# GD32E511_512 register map
File version: 1.0
CPU: CM33 r0p4, little endian, MPU, FPU, 4 interrupt priority bits
Registers are 32-bit, read-write, reset 0x0 unless marked. A register's access mark holds for its fields unless they carry their own. Offsets are from the block's base; [hi:lo] are bit positions; {n}, {i} and the like mark numbered series.

## I3C — Improved inter-integrated circuit interface
Base 0x40015C00
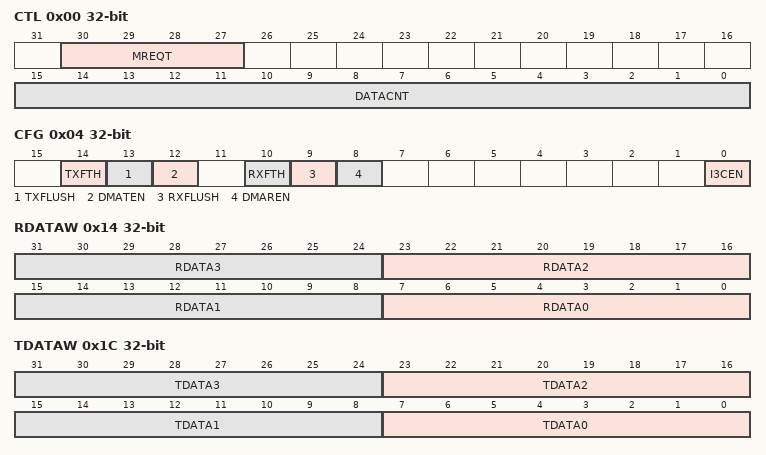
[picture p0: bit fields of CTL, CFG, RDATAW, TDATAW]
0x00 CTL wo — Control register
  [30:27] MREQT — Target message request type
  [15:0] DATACNT — The number of data bytes transmitted
0x04 CFG — Configuration register
  [14] TXFTH — TX-FIFO threshold
  [13] TXFLUSH — TX-FIFO flush
  [12] DMATEN — TX-FIFO DMA request enable
  [10] RXFTH — RX-FIFO threshold
  [9] RXFLUSH — RX-FIFO flush.
  [8] DMAREN — RX-FIFO DMA request enable
  [0] I3CEN — I3C enable
0x10 RDATAB ro — Receive data byte register
  [7:0] RDATA0 — 8-bit received data
0x14 RDATAW ro — Receive data word register
  [8n+7:8n] RDATA{n} (n=0..3) — 8-bit received data
0x18 TDATAB wo — Transmit data byte register
  [7:0] TDATA0 — 8-bit data to transmit
0x1C TDATAW wo — Transmit data word register
  [8n+7:8n] TDATA{n} (n=0..3) — 8-bit transmit data
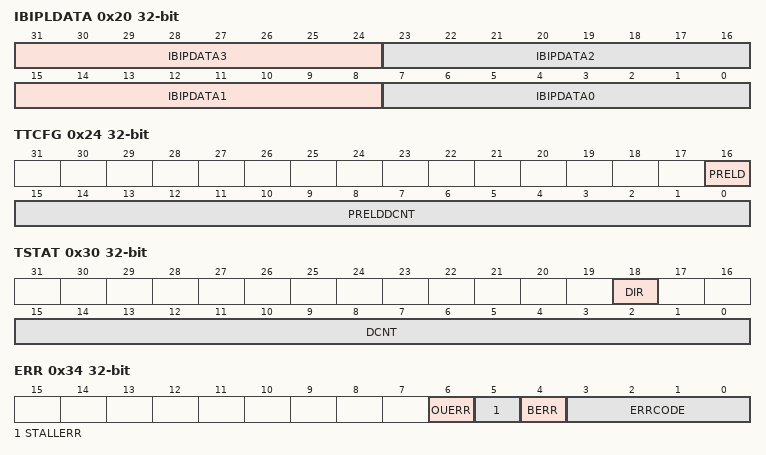
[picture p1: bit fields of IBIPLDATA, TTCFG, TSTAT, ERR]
0x20 IBIPLDATA — IBI Payload data register
  [31:24] IBIPDATA3 — 8-bit IBI payload data
  [23:16] IBIPDATA2 — 8-bit IBI payload data
  [15:8] IBIPDATA1 — 8-bit IBI payload data
  [7:0] IBIPDATA0 — 8-bit IBI payload data (earliest byte on I3C bus, MDB[7:0] mandatory data byte). Data byte to go with an IBI, if enabled for it. If enabled (BCR2 bit is set), then it is required.
0x24 TTCFG — Target transmit configuration registe
  [16] PRELD — Preload of the TX-FIFO
  [15:0] PRELDDCNT — The number of bytes preloaded into the TXFIFO, used in conjunction with the PRELD bit.
0x30 TSTAT ro — Transmit status register
  [18] DIR — I3C bus message transmit direction
  [15:0] DCNT — During the dynamic address assignment process (ENTDAA CCC), this bit field indicates the number of transmitted bytes
0x34 ERR ro — Error status register
  [6] OUERR — RXFIFO overrun or TXFIFO underrun
  [5] STALLERR — SCL stall error
  [4] BERR — Bus protocol error
  [3:0] ERRCODE — Protocol error code/type
0x40 RMES ro — Received message register
  [15:8] RCODE — Received CCC code
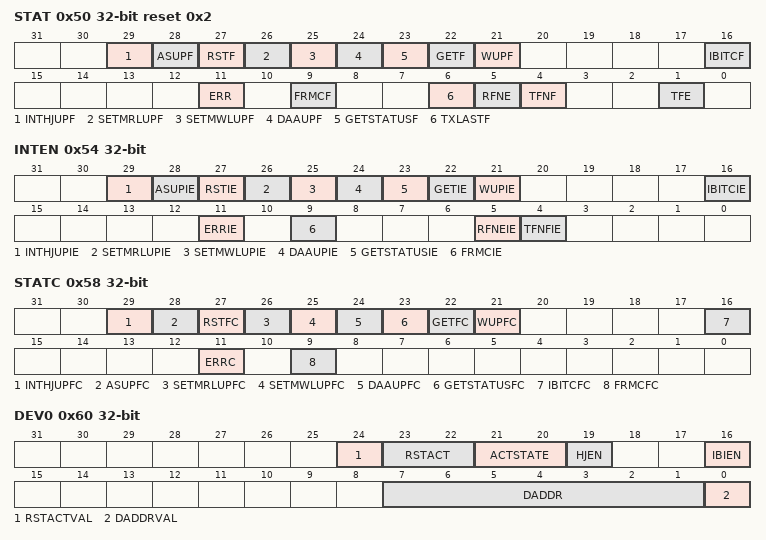
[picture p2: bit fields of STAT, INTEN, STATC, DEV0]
0x50 STAT ro reset 0x2 — Status register
  [29] INTHJUPF — Interrupt/hot-join update flag
  [28] ASUPF — Activity state update flag
  [27] RSTF — Reset pattern flag
  [26] SETMRLUPF — Maximum read length update flag
  [25] SETMWLUPF — Maximum write length update flag
  [24] DAAUPF — Dynamic address update flag
  [23] GETSTATUSF — Get status flag
  [22] GETF — Get flag
  [21] WUPF — Wake-up/missed start flag
  [16] IBITCF — IBI transmit completed flag
  [11] ERR — Error flag
  [9] FRMCF — Private read/write frame completed flag
  [6] TXLASTF — TXFIFO last data byte/word flag (data or word depending upon TXFTH in the I3C_CFG register)
  [5] RFNE — RX-FIFO not empty flag
  [4] TFNF — TX-FIFO not full flag
  [1] TFE — TX-FIFO empty flag
0x54 INTEN — Interrupt enable register
  [29] INTHJUPIE — ENEC/DISEC CCC interrupt enable
  [28] ASUPIE — ENTASx CCC interrupt enable
  [27] RSTIE — Reset pattern interrupt enable
  [26] SETMRLUPIE — SETMRL CCC interrupt enable
  [25] SETMWLUPIE — SETMWL CCC interrupt enable
  [24] DAAUPIE — ENTDAA/RSTDAA/SETNEWDA CCC interrupt enable
  [23] GETSTATUSIE — GETSTATUS CCC format 1 interrupt enable
  [22] GETIE — GETxxx CCC interrupt enable (except GETSTATUS of format 1)
  [21] WUPIE — Wake-up interrupt enable
  [16] IBITCIE — IBI completed interrupt enable
  [11] ERRIE — Error interrupt enable
  [9] FRMCIE — Frame completed interrupt enable
  [5] RFNEIE — RX-FIFO not empty interrupt enable
  [4] TFNFIE — TX-FIFO not full interrupt enable
0x58 STATC wo — Status clear register
  [29] INTHJUPFC — Set this bit to clear INTHJUPF flag in I3C_STAT register
  [28] ASUPFC — Set this bit to clear ASUPF flag in I3C_STAT register
  [27] RSTFC — Set this bit to clear RSTF flag in I3C_STAT register
  [26] SETMRLUPFC — Set this bit to clear SETMRLUPF flag in I3C_STAT register
  [25] SETMWLUPFC — Set this bit to clear SETMWLUPF flag in I3C_STAT register
  [24] DAAUPFC — Set this bit to clear DAAUPF flag in I3C_STAT register
  [23] GETSTATUSFC — Set this bit to clear GETSTATUSF flag in I3C_STAT register
  [22] GETFC — Set this bit to clear GETF flag in I3C_STAT register
  [21] WUPFC — Set this bit to clear WUPF flag in I3C_STAT register
  [16] IBITCFC — Set this bit to clear IBITCF flag in I3C_STAT register
  [11] ERRC — Set this bit to clear ERR flag in I3C_STAT register
  [9] FRMCFC — Set this bit to clear FRMCF flag in I3C_STAT register
0x60 DEV0 access per field — Own device characteristics register
  [24] RSTACTVAL ro — Reset action is valid
  [23:22] RSTACT ro — Reset action/level on received reset pattern
  [21:20] ACTSTATE ro — Activity state
  [19] HJEN rw — Hot-join request enable
  [16] IBIEN rw — IBI request enable
  [7:1] DADDR ro — 7-bit dynamic address
  [0] DADDRVAL ro — Dynamic address is valid
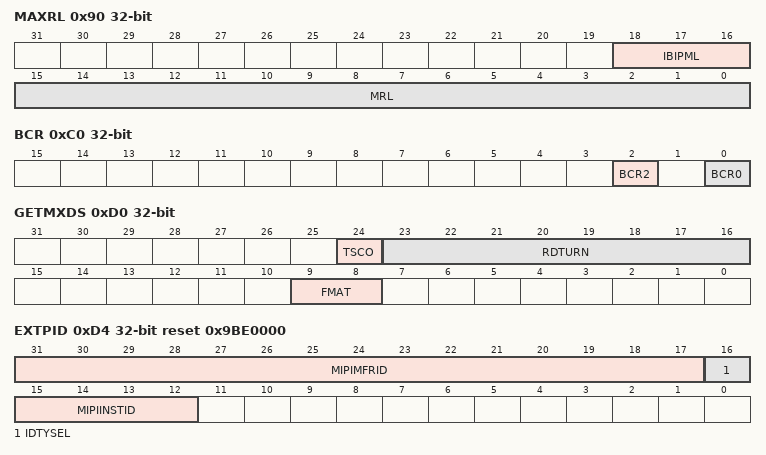
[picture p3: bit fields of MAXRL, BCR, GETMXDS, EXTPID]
0x90 MAXRL — Maximum read length register
  [18:16] IBIPML — Maximum number of bytes for IBI payload data
  [15:0] MRL — Maximum number of bytes for data read length
0x94 MAXWL — Maximum write length register
  [15:0] MWL — Maximum number of bytes for data write length
0xA4 TIMING1 — Timing register 1
  [7:0] AVALCLK — Number of kernel clock cycles to set a time unit of 1 's. This time unit is used to construct some internal timers.
0xC0 BCR — Bus characteristics register
  [2] BCR2 — IBI payload
  [0] BCR0 — Max data speed limitation
0xC4 DCR — Device characteristics register
  [7:0] DCR — Device characteristics ID
0xC8 GETCAP — Get capability register
  [14] CAP3PEND — IBI MDB support for pending read notification
0xD0 GETMXDS — Get max data speed register
  [24] TSCO — Clock-to-data turnaround time (tSCO)
  [23:16] RDTURN — Programmed byte of the 3-byte MaxRdTurn
  [9:8] FMAT — GETMXDS CCC format
0xD4 EXTPID access per field reset 0x9BE0000 — Extended provisioned ID register
  [31:17] MIPIMFRID ro — 15-bit MIPI manufacturer ID
  [16] IDTYSEL ro — Provisioned ID type selector
  [15:12] MIPIINSTID rw — 4-bit MIPI Instance ID
